# SWM330 register map
File version: 1.0
CPU: CM0 r1p0, little endian, 2 interrupt priority bits
Registers are 32-bit, read-write, no defined reset value unless marked. A register's access mark holds for its fields unless they carry their own. Offsets are from the block's base; [hi:lo] are bit positions; lines under a group give offsets from that group; {n}, {i} and the like mark numbered series; 'fields as' and 'values as' point back to an identical list.

## GPIOA — Registers group
Base 0x40040000
Same registers: GPIOB 0x40040800, GPIOC 0x40041000, GPIOD 0x40041800, GPIOE 0x400A6000
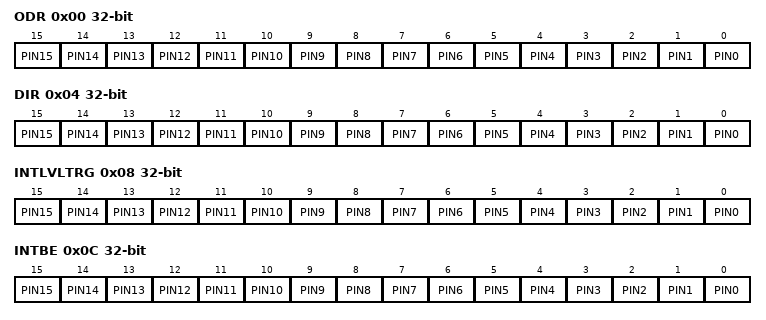
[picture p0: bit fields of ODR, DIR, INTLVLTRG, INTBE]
0x00 ODR
  [n] PIN{n} (n=0..15)
0x04 DIR
  [n] PIN{n} (n=0..15)
0x08 INTLVLTRG
  [n] PIN{n} (n=0..15)
0x0C INTBE
  [n] PIN{n} (n=0..15)
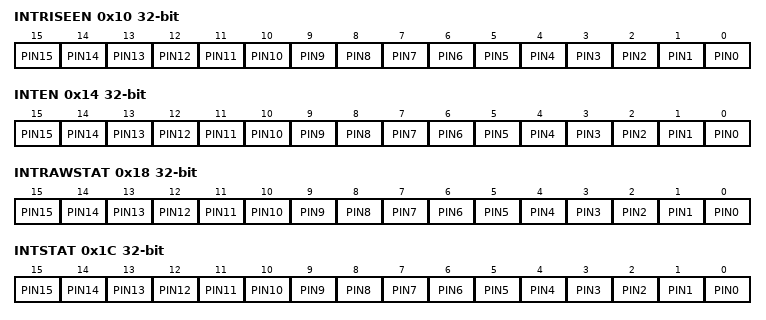
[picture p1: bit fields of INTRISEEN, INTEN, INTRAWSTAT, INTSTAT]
0x10 INTRISEEN
  [n] PIN{n} (n=0..15)
0x14 INTEN
  [n] PIN{n} (n=0..15)
0x18 INTRAWSTAT ro
  [n] PIN{n} (n=0..15)
0x1C INTSTAT ro
  [n] PIN{n} (n=0..15)
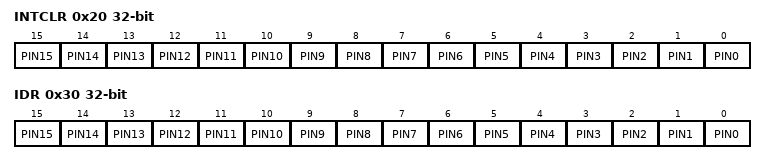
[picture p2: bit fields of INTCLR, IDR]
0x20 INTCLR wo
  [n] PIN{n} (n=0..15)
0x30 IDR ro
  [n] PIN{n} (n=0..15)
{0x40+4i} DATAPIN{i} (i=0..15)

## TIMR0 — Registers group
Base 0x40044000
Same registers: TIMR1 0x40044040, BTIMR0 0x40044800, BTIMR1 0x40044840, BTIMR2 0x40044880, BTIMR3 0x400448C0
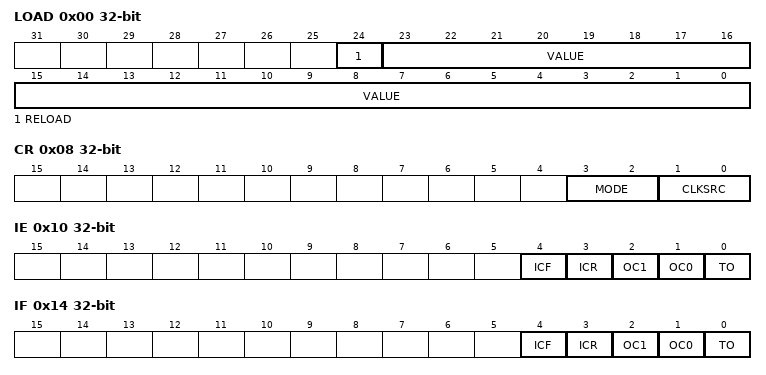
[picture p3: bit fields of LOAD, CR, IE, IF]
0x00 LOAD
  [24] RELOAD, [23:0] VALUE
0x04 VALUE ro
0x08 CR
  [3:2] MODE, [1:0] CLKSRC
0x10 IE
  [4] ICF, [3] ICR, [2] OC1, [1] OC0, [0] TO
0x14 IF
  [4] ICF, [3] ICR, [2] OC1, [1] OC0, [0] TO
0x18 HALT
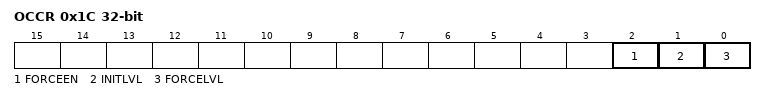
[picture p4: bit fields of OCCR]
0x1C OCCR
  [2] FORCEEN, [1] INITLVL, [0] FORCELVL
0x20 OCMAT
0x28 ICLOW
0x2C ICHIGH
0x30 PREDIV

## TIMRG — Registers group
Base 0x40044400
Same registers: BTIMRG 0x40044C00
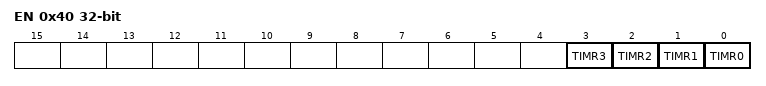
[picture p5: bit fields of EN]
0x40 EN
  [n] TIMR{n} (n=0..3)

## UART0 — Registers group
Base 0x400A1000
Same registers: UART1 0x400A1800, UART2 0x400A2000, UART3 0x400A2800, UART4 0x400A3000
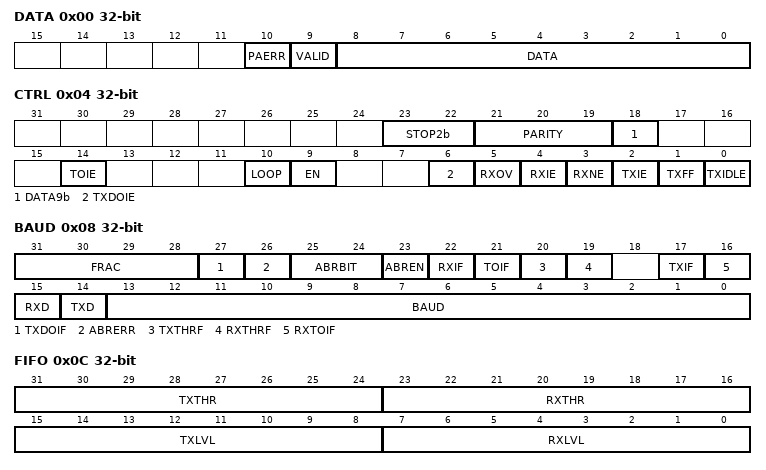
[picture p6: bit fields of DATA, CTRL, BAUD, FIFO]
0x00 DATA
  [10] PAERR, [9] VALID, [8:0] DATA
0x04 CTRL
  [23:22] STOP2b, [21:19] PARITY, [18] DATA9b, [14] TOIE, [10] LOOP, [9] EN, [6] TXDOIE, [5] RXOV, [4] RXIE, [3] RXNE, [2] TXIE, [1] TXFF, [0] TXIDLE
0x08 BAUD
  [31:28] FRAC, [27] TXDOIF, [26] ABRERR, [25:24] ABRBIT, [23] ABREN, [22] RXIF, [21] TOIF, [20] TXTHRF, [19] RXTHRF, [17] TXIF, [16] RXTOIF, [15] RXD, [14] TXD, [13:0] BAUD
0x0C FIFO
  [31:24] TXTHR, [23:16] RXTHR, [15:8] TXLVL, [7:0] RXLVL
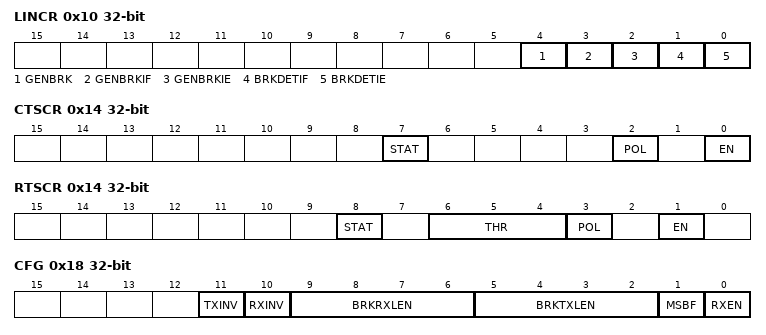
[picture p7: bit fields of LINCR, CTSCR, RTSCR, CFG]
0x10 LINCR
  [4] GENBRK, [3] GENBRKIF, [2] GENBRKIE, [1] BRKDETIF, [0] BRKDETIE
0x14 CTSCR
  [7] STAT, [2] POL, [0] EN
0x14 RTSCR (alternate view of CTSCR)
  [8] STAT, [6:4] THR, [3] POL, [1] EN
0x18 CFG
  [11] TXINV, [10] RXINV, [9:6] BRKRXLEN, [5:2] BRKTXLEN, [1] MSBF, [0] RXEN
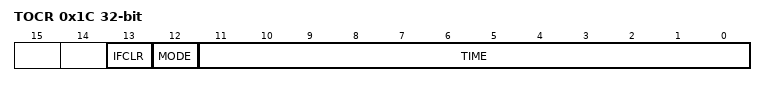
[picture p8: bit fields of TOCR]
0x1C TOCR
  [13] IFCLR, [12] MODE, [11:0] TIME

## SPI0 — Registers group
Base 0x40042000
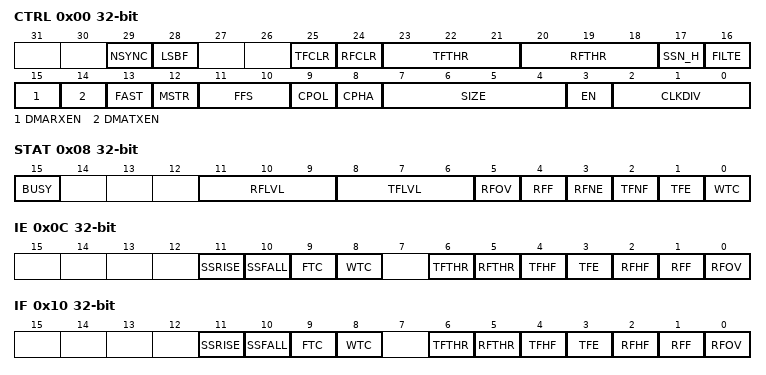
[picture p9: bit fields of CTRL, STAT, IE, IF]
0x00 CTRL
  [29] NSYNC, [28] LSBF, [25] TFCLR, [24] RFCLR, [23:21] TFTHR, [20:18] RFTHR, [17] SSN_H, [16] FILTE, [15] DMARXEN, [14] DMATXEN, [13] FAST, [12] MSTR, [11:10] FFS, [9] CPOL, [8] CPHA, [7:4] SIZE, [3] EN, [2:0] CLKDIV
0x04 DATA
0x08 STAT
  [15] BUSY, [11:9] RFLVL, [8:6] TFLVL, [5] RFOV, [4] RFF, [3] RFNE, [2] TFNF, [1] TFE, [0] WTC
0x0C IE
  [11] SSRISE, [10] SSFALL, [9] FTC, [8] WTC, [6] TFTHR, [5] RFTHR, [4] TFHF, [3] TFE, [2] RFHF, [1] RFF, [0] RFOV
0x10 IF
  fields as IE

## I2S0 — Registers group
Base 0x40042800
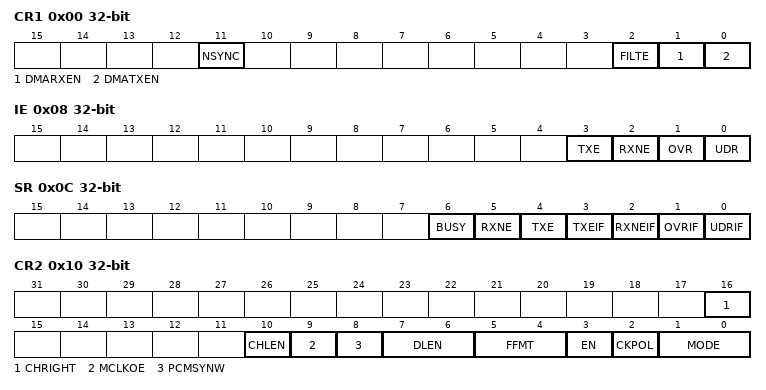
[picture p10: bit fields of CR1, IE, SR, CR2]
0x00 CR1
  [11] NSYNC, [2] FILTE, [1] DMARXEN, [0] DMATXEN
0x04 DR
0x08 IE
  [3] TXE, [2] RXNE, [1] OVR, [0] UDR
0x0C SR
  [6] BUSY, [5] RXNE, [4] TXE, [3] TXEIF, [2] RXNEIF, [1] OVRIF, [0] UDRIF
0x10 CR2
  [16] CHRIGHT, [10] CHLEN, [9] MCLKOE, [8] PCMSYNW, [7:6] DLEN, [5:4] FFMT, [3] EN, [2] CKPOL, [1:0] MODE
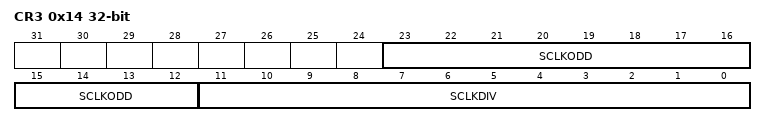
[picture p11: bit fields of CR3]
0x14 CR3
  [23:12] SCLKODD, [11:0] SCLKDIV

## I2C0 — Registers group
Base 0x400A4000
Same registers: I2C1 0x400A4800
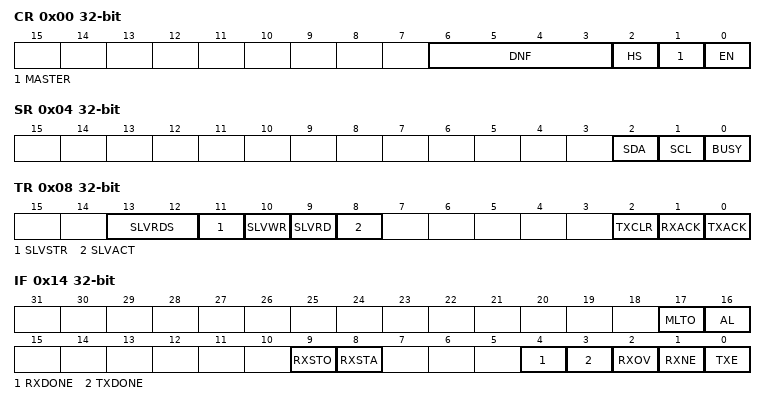
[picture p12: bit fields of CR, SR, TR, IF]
0x00 CR
  [6:3] DNF, [2] HS, [1] MASTER, [0] EN
0x04 SR
  [2] SDA, [1] SCL, [0] BUSY
0x08 TR
  [13:12] SLVRDS, [11] SLVSTR, [10] SLVWR, [9] SLVRD, [8] SLVACT, [2] TXCLR, [1] RXACK, [0] TXACK
0x0C RXDATA
0x10 TXDATA
0x14 IF
  [17] MLTO, [16] AL, [9] RXSTO, [8] RXSTA, [4] RXDONE, [3] TXDONE, [2] RXOV, [1] RXNE, [0] TXE
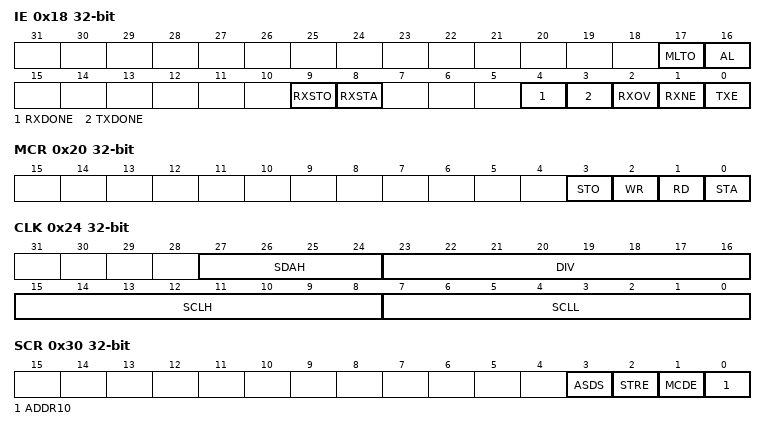
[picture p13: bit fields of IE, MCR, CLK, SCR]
0x18 IE
  fields as IF
0x20 MCR
  [3] STO, [2] WR, [1] RD, [0] STA
0x24 CLK
  [27:24] SDAH, [23:16] DIV, [15:8] SCLH, [7:0] SCLL
0x30 SCR
  [3] ASDS, [2] STRE, [1] MCDE, [0] ADDR10
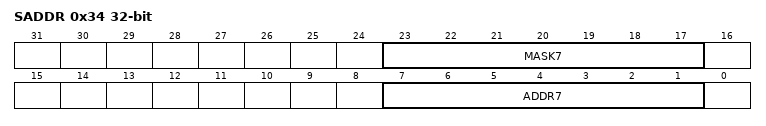
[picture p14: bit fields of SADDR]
0x34 SADDR
  [23:17] MASK7, [7:1] ADDR7
